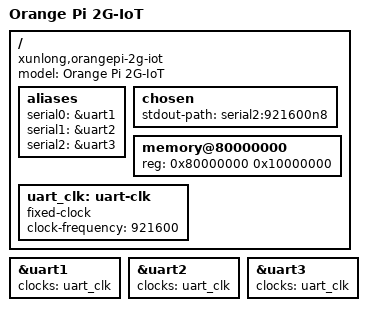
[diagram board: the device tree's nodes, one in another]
/* bench 12711.2.0 fe19b8ff75ca */
/* bench 12711.2.1 ca8c35e658a5 */
/* bench 12711.2.2 20a738c4b29c */
/* bench 12711.2.3 89204b56177f */
/* bench 12711.2.4 d9839e43e27d */
/* bench 12711.2.5 4be96b41c838 */
/* bench 12711.2.6 196ae95826ac */
/* bench 12711.2.7 488790efb1d7 */
/* bench 12711.2.8 6a26c3ed9a41 */
/* bench 12711.2.9 24f4f6c4e501 */
// SPDX-License-Identifier: (GPL-2.0+ OR MIT)
/*
 * Copyright (c) 2017 Andreas Färber
 * Copyright (c) 2018 Manivannan Sadhasivam
 */

/dts-v1/;

#include "rda8810pl.dtsi"

/ {
	compatible = "xunlong,orangepi-2g-iot", "rda,8810pl";
	model = "Orange Pi 2G-IoT";

	aliases {
		serial0 = &uart1;
		serial1 = &uart2;
		serial2 = &uart3;
	};

	chosen {
		stdout-path = "serial2:921600n8";
	};

	memory@80000000 {
		device_type = "memory";
		reg = <0x80000000 0x10000000>;
	};

	uart_clk: uart-clk {
		compatible = "fixed-clock";
		clock-frequency = <921600>;
		#clock-cells = <0>;
	};
};

&uart1 {
	status = "okay";
	clocks = <&uart_clk>;
};

&uart2 {
	status = "okay";
	clocks = <&uart_clk>;
};

&uart3 {
	status = "okay";
	clocks = <&uart_clk>;
};
